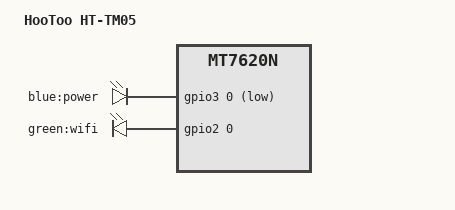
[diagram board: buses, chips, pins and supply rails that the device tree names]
// SPDX-License-Identifier: GPL-2.0-or-later OR MIT

#include "mt7620n_sunvalley_filehub.dtsi"

/ {
	compatible = "hootoo,ht-tm05", "ralink,mt7620n-soc";
	model = "HooToo HT-TM05";

	aliases {
		led-boot = &led_power;
		led-failsafe = &led_power;
		led-running = &led_power;
		led-upgrade = &led_power;
	};

	leds {
		compatible = "gpio-leds";

		led_power: power {
			label = "blue:power";
			gpios = <&gpio3 0 GPIO_ACTIVE_LOW>;
			default-state = "on";
		};

		wifi {
			label = "green:wifi";
			gpios = <&gpio2 0 GPIO_ACTIVE_HIGH>;
			linux,default-trigger = "phy0tpt";
		};
	};
};
